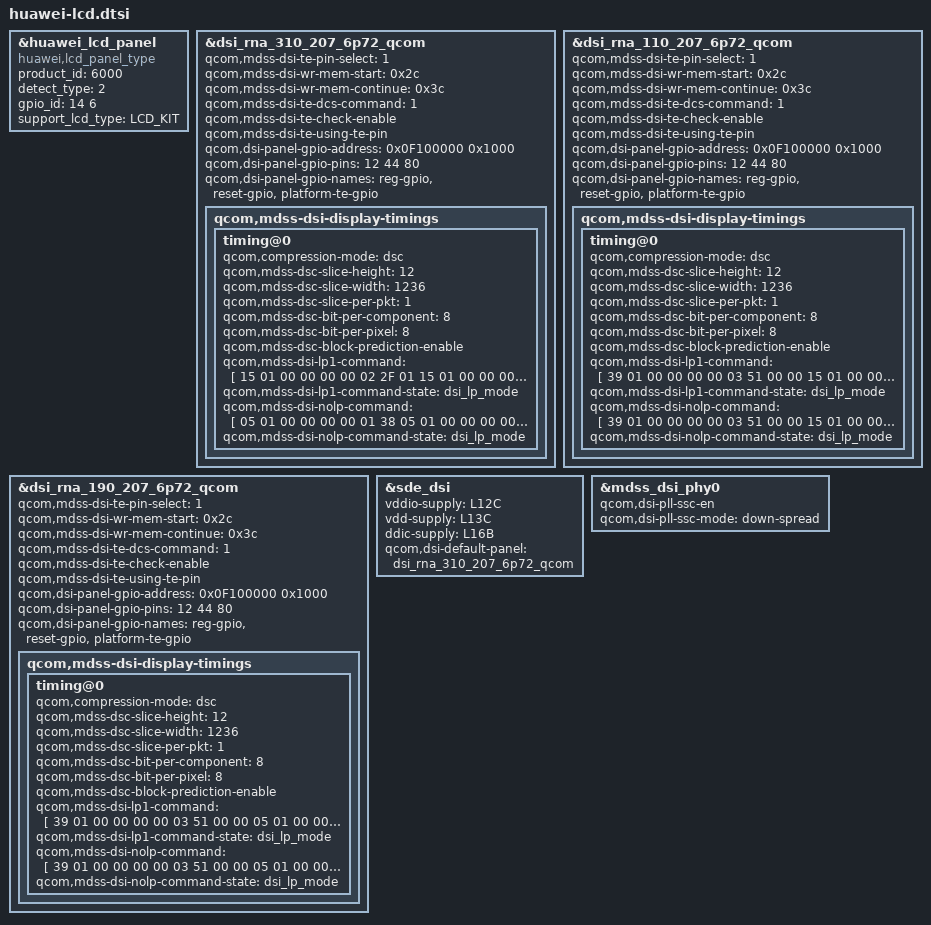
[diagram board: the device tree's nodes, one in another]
#include "../../../lcdkit3.0/rna/devkit_lcd_kit.dtsi"
&huawei_lcd_panel {
	compatible = "huawei,lcd_panel_type";
	/* auto_key_info @ name: product_id type: uint32 default: 0 */
	product_id = <6000>;
	detect_type = <2>;
	/* auto_key_info @ name: gpio_id[2] type: int default: 0 */
	gpio_id = <14 6>;
	support_lcd_type = "LCD_KIT";
};

&dsi_rna_310_207_6p72_qcom {
	qcom,mdss-dsi-te-pin-select = <1>;
	qcom,mdss-dsi-wr-mem-start = <0x2c>;
	qcom,mdss-dsi-wr-mem-continue = <0x3c>;
	qcom,mdss-dsi-te-dcs-command = <1>;
	qcom,mdss-dsi-te-check-enable;
	qcom,mdss-dsi-te-using-te-pin;
	qcom,dsi-panel-gpio-address = <0x0F100000 0x1000>;
	qcom,dsi-panel-gpio-pins = <12 44 80>;
	qcom,dsi-panel-gpio-names = "reg-gpio", "reset-gpio", "platform-te-gpio";
	qcom,mdss-dsi-display-timings {
		timing@0 {
			qcom,compression-mode = "dsc";
			qcom,mdss-dsc-slice-height = <12>;
			qcom,mdss-dsc-slice-width = <1236>;
			qcom,mdss-dsc-slice-per-pkt = <1>;
			qcom,mdss-dsc-bit-per-component = <8>;
			qcom,mdss-dsc-bit-per-pixel = <8>;
			qcom,mdss-dsc-block-prediction-enable;
			qcom,mdss-dsi-lp1-command = [
				15 01 00 00 00 00 02 2F 01
				15 01 00 00 00 00 02 6F 02
				39 01 00 00 00 00 03 51 0F FE
				05 01 00 00 00 00 01 39
				05 01 00 00 00 00 01 2C
			];
			qcom,mdss-dsi-lp1-command-state = "dsi_lp_mode";
			qcom,mdss-dsi-nolp-command = [
				05 01 00 00 00 00 01 38
				05 01 00 00 00 00 01 2C
			];
			qcom,mdss-dsi-nolp-command-state = "dsi_lp_mode";
		};
	};
};

&dsi_rna_110_207_6p72_qcom {
	qcom,mdss-dsi-te-pin-select = <1>;
	qcom,mdss-dsi-wr-mem-start = <0x2c>;
	qcom,mdss-dsi-wr-mem-continue = <0x3c>;
	qcom,mdss-dsi-te-dcs-command = <1>;
	qcom,mdss-dsi-te-check-enable;
	qcom,mdss-dsi-te-using-te-pin;
	qcom,dsi-panel-gpio-address = <0x0F100000 0x1000>;
	qcom,dsi-panel-gpio-pins = <12 44 80>;
	qcom,dsi-panel-gpio-names = "reg-gpio", "reset-gpio", "platform-te-gpio";
	qcom,mdss-dsi-display-timings {
		timing@0 {
			qcom,compression-mode = "dsc";
			qcom,mdss-dsc-slice-height = <12>;
			qcom,mdss-dsc-slice-width = <1236>;
			qcom,mdss-dsc-slice-per-pkt = <1>;
			qcom,mdss-dsc-bit-per-component = <8>;
			qcom,mdss-dsc-bit-per-pixel = <8>;
			qcom,mdss-dsc-block-prediction-enable;
			qcom,mdss-dsi-lp1-command = [
				39 01 00 00 00 00 03 51 00 00
				15 01 00 00 00 00 02 65 00
				05 01 00 00 00 00 01 39
				05 01 00 22 00 00 01 2C
			];
			qcom,mdss-dsi-lp1-command-state = "dsi_lp_mode";
			qcom,mdss-dsi-nolp-command = [
				39 01 00 00 00 00 03 51 00 00
				15 01 00 00 00 00 02 65 00
				05 01 00 00 00 00 01 38
				05 01 00 22 00 00 01 2C
			];
			qcom,mdss-dsi-nolp-command-state = "dsi_lp_mode";
		};
	};
};

&dsi_rna_190_207_6p72_qcom {
	qcom,mdss-dsi-te-pin-select = <1>;
	qcom,mdss-dsi-wr-mem-start = <0x2c>;
	qcom,mdss-dsi-wr-mem-continue = <0x3c>;
	qcom,mdss-dsi-te-dcs-command = <1>;
	qcom,mdss-dsi-te-check-enable;
	qcom,mdss-dsi-te-using-te-pin;
	qcom,dsi-panel-gpio-address = <0x0F100000 0x1000>;
	qcom,dsi-panel-gpio-pins = <12 44 80>;
	qcom,dsi-panel-gpio-names = "reg-gpio", "reset-gpio", "platform-te-gpio";
	qcom,mdss-dsi-display-timings {
		timing@0 {
			qcom,compression-mode = "dsc";
			qcom,mdss-dsc-slice-height = <12>;
			qcom,mdss-dsc-slice-width = <1236>;
			qcom,mdss-dsc-slice-per-pkt = <1>;
			qcom,mdss-dsc-bit-per-component = <8>;
			qcom,mdss-dsc-bit-per-pixel = <8>;
			qcom,mdss-dsc-block-prediction-enable;
			qcom,mdss-dsi-lp1-command = [
				39 01 00 00 00 00 03 51 00 00
				05 01 00 00 00 00 01 39
				05 01 00 22 00 00 01 2C
			];
			qcom,mdss-dsi-lp1-command-state = "dsi_lp_mode";
			qcom,mdss-dsi-nolp-command = [
				39 01 00 00 00 00 03 51 00 00
				05 01 00 00 00 00 01 38
				05 01 00 22 00 00 01 2C
			];
			qcom,mdss-dsi-nolp-command-state = "dsi_lp_mode";
		};
	};
};

&sde_dsi {
	vddio-supply = <&L12C>;
	vdd-supply = <&L13C>;
	ddic-supply = <&L16B>;
	qcom,dsi-default-panel = <&dsi_rna_310_207_6p72_qcom>;
};
&mdss_dsi_phy0 {
    qcom,dsi-pll-ssc-en;
    qcom,dsi-pll-ssc-mode = "down-spread";
};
